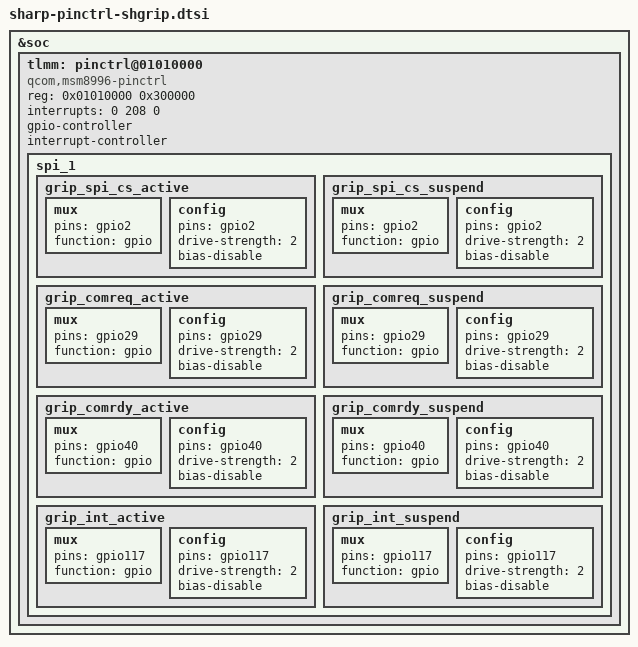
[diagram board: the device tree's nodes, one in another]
/* Copyright (c) 2014-2015, The Linux Foundation. All rights reserved.
 *
 * This program is free software; you can redistribute it and/or modify
 * it under the terms of the GNU General Public License version 2 and
 * only version 2 as published by the Free Software Foundation.
 *
 * This program is distributed in the hope that it will be useful,
 * but WITHOUT ANY WARRANTY; without even the implied warranty of
 * MERCHANTABILITY or FITNESS FOR A PARTICULAR PURPOSE.  See the
 * GNU General Public License for more details.
 */

&soc {
	tlmm: pinctrl@01010000 {
		compatible = "qcom,msm8996-pinctrl";
		reg = <0x01010000 0x300000>;
		interrupts = <0 208 0>;
		gpio-controller;
		#gpio-cells = <2>;
		interrupt-controller;
		#interrupt-cells = <2>;

		/*****************************************/
		/*	SPI									 */
		/*****************************************/
		spi_1 {

			grip_spi_cs_active: grip_spi_cs_active {
				mux {
					pins = "gpio2";
					function = "gpio";
				};
				config {
					pins = "gpio2";
					drive-strength = <2>;
					bias-disable;
				};
			};
			
			grip_spi_cs_suspend: grip_spi_cs_suspend {
				mux {
					pins = "gpio2";
					function = "gpio";
				};
				config {
					pins = "gpio2";
					drive-strength = <2>;
					bias-disable;
				};
			};
            
			grip_comreq_active: grip_comreq_active {
				mux {
					pins = "gpio29";
					function = "gpio";
				};
				config {
					pins = "gpio29";
					drive-strength = <2>;
					bias-disable;
				};
			};
			
			grip_comreq_suspend: grip_comreq_suspend {
				mux {
					pins = "gpio29";
					function = "gpio";
				};
				config {
					pins = "gpio29";
					drive-strength = <2>;
					bias-disable;
				};
			};
			
			grip_comrdy_active: grip_comrdy_active {
				mux {
					pins = "gpio40";
					function = "gpio";
				};
				config {
					pins = "gpio40";
					drive-strength = <2>;
					bias-disable;
				};
			};
			grip_comrdy_suspend: grip_comrdy_suspend {
				mux {
					pins = "gpio40";
					function = "gpio";
				};
				config {
					pins = "gpio40";
					drive-strength = <2>;
					bias-disable;
				};
			};
			
			grip_int_active: grip_int_active {
				mux {
					pins = "gpio117";
					function = "gpio";
				};
				config {
					pins = "gpio117";
					drive-strength = <2>;
					bias-disable;
				};
			};
			grip_int_suspend: grip_int_suspend {
				mux {
					pins = "gpio117";
					function = "gpio";
				};
				config {
					pins = "gpio117";
					drive-strength = <2>;
					bias-disable;
				};
			};
		};
	};
};
